# BE-U1000 register map
Vendor: BAIKAL ELECTRONICS, JSC; File version: 1.0
CPU: RISC-V r0p0, little endian, no MPU, no FPU, 3 interrupt priority bits
Registers are 32-bit, read-write, reset 0x0 unless marked. A register's access mark holds for its fields unless they carry their own. Offsets are from the block's base; [hi:lo] are bit positions; {n}, {i} and the like mark numbered series; 'fields as' and 'values as' point back to an identical list.

## CANFD0 — Controller Area Network
Base 0x11010000
Same registers: CANFD1 0x13010000
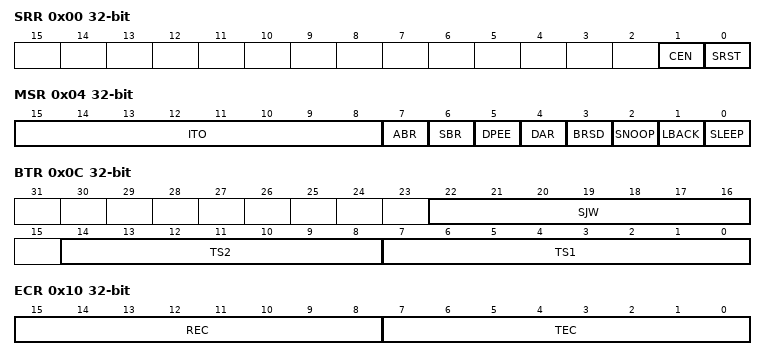
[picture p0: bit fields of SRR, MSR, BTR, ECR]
0x00 SRR — Software Reset Register
  [1] CEN — CAN enable
    0=DISABLE; 1=ENABLE
  [0] SRST — Reset
    0=DISABLE; 1=ENABLE
0x04 MSR — Mode Select Register
  [15:8] ITO — Internal timing optimization
  [7] ABR — Auto bus-off recovery request
    0=DISABLE; 1=ENABLE
  [6] SBR — Start bus-off recovery request
    0=DISABLE; 1=ENABLE
  [5] DPEE — Disable protocol exception event detection/generation
    0=DISABLE; 1=ENABLE
  [4] DAR — Disable auto retransmission
    0=DISABLE; 1=ENABLE
  [3] BRSD — CAN FD bitrate switch disable override
    0=DISABLE; 1=ENABLE
  [2] SNOOP — Snoop mode select/request
    0=DISABLE; 1=ENABLE
  [1] LBACK — Loopback mode select/request
    0=DISABLE; 1=ENABLE
  [0] SLEEP — Sleep mode select/request
    0=DISABLE; 1=ENABLE
0x08 BRPR — Arbitration Phase Baud Rate Prescaler Register
  [7:0] PR — Arbitration phase baudrate prescaler
0x0C BTR — Arbitration Phase Bit Timing Register
  [22:16] SJW — Synchronization jump width
  [14:8] TS2 — Time segment 2
  [7:0] TS1 — Time segment 1
0x10 ECR — Error Counter Register
  [15:8] REC — Receive error count
  [7:0] TEC — Transmit error count
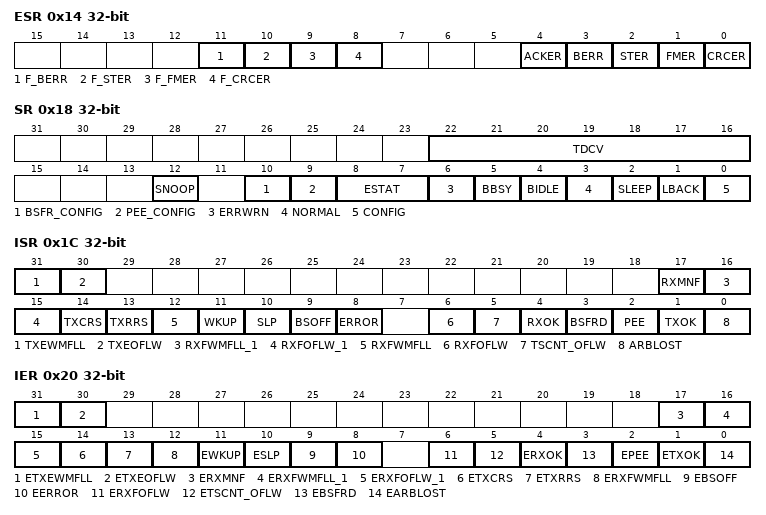
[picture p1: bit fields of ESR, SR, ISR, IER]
0x14 ESR — Error Status Register
  [all] fields
    0=DISABLE; 1=ENABLE
  [11] F_BERR — Bit error in CAN FD data phase
  [10] F_STER — Stuff error in CAN FD data phase
  [9] F_FMER — Form error in CAN FD data phase
  [8] F_CRCER — CRC error in CAN FD data phase
  [4] ACKER — ACK error
  [3] BERR — Bit error
  [2] STER — Stuff error
  [1] FMER — Form error
  [0] CRCER — CRC error
0x18 SR — Status Register
  [22:16] TDCV — Transmitter delay compensation value
  [12] SNOOP — Snoop mode
    0=DISABLE; 1=ENABLE
  [10] BSFR_CONFIG — Bus-off recovery mode indicator
    0=DISABLE; 1=ENABLE
  [9] PEE_CONFIG — PEE mode indicator
    0=DISABLE; 1=ENABLE
  [8:7] ESTAT — Error status
    0=CONFIG (Configuration mode, error state is undefined); 1=ACTIVE (Error active state); 2=BUSOFF (Bus-off state); 3=PASSIVE (Error passive state)
  [6] ERRWRN — Error warning
    0=DISABLE; 1=ENABLE
  [5] BBSY — Bus busy
    0=DISABLE; 1=ENABLE
  [4] BIDLE — Bus idle
    0=DISABLE; 1=ENABLE
  [3] NORMAL — Normal mode
    0=DISABLE; 1=ENABLE
  [2] SLEEP — Sleep mode
    0=DISABLE; 1=ENABLE
  [1] LBACK — Loopback mode
    0=DISABLE; 1=ENABLE
  [0] CONFIG — Configuration mode indicator
    0=DISABLE; 1=ENABLE
0x1C ISR — Interrupt Status Register
  [all] fields
    0=DISABLE; 1=ENABLE
  [31] TXEWMFLL — Tx event FIFO watermark full interrupt
  [30] TXEOFLW — Tx event FIFO overflow interrupt
  [17] RXMNF — Rx match not finished interrupt
  [16] RXFWMFLL_1 — Rx FIFO-1 watermark full interrupt
  [15] RXFOFLW_1 — Rx FIFO-1 overflow interrupt
  [14] TXCRS — Tx cancellation request served interrupt
  [13] TXRRS — Tx buffer ready request served interrupt
  [12] RXFWMFLL — Rx FIFO-0 watermark full interrupt
  [11] WKUP — Wake-up interrupt
  [10] SLP — Sleep interrupt
  [9] BSOFF — Bus-off interrupt
  [8] ERROR — Error interrupt
  [6] RXFOFLW — Rx FIFO-0 overflow interrupt
  [5] TSCNT_OFLW — Timestamp counter overflow interrupt
  [4] RXOK — New message received interrupt
  [3] BSFRD — Bus-off recovery done interrupt
  [2] PEE — Protocol exception event interrupt
  [1] TXOK — Transmission successful interrupt
  [0] ARBLOST — Arbitration lost interrupt
0x20 IER — Interrupt Enable Register
  [all] fields
    0=DISABLE; 1=ENABLE
  [31] ETXEWMFLL — Tx event FIFO watermark full interrupt enable
  [30] ETXEOFLW — Tx event FIFO overflow interrupt enable
  [17] ERXMNF — Rx match not finished interrupt enable
  [16] ERXFWMFLL_1 — Rx FIFO-1 watermark full interrupt enable
  [15] ERXFOFLW_1 — Rx FIFO-1 overflow interrupt enable
  [14] ETXCRS — Tx cancellation request served interrupt enable
  [13] ETXRRS — Tx buffer ready request served interrupt enable
  [12] ERXFWMFLL — Rx FIFO-0 watermark full interrupt enable
  [11] EWKUP — Wake-up interrupt enable
  [10] ESLP — Sleep interrupt enable
  [9] EBSOFF — Bus-off interrupt enable
  [8] EERROR — Error interrupt enable
  [6] ERXFOFLW — Rx FIFO-0 overflow interrupt enable
  [5] ETSCNT_OFLW — Timestamp counter overflow interrupt enable
  [4] ERXOK — New message received interrupt enable
  [3] EBSFRD — Bus-off recovery done interrupt enable
  [2] EPEE — Protocol exception event interrupt enable
  [1] ETXOK — Transmission successful interrupt enable
  [0] EARBLOST — Arbitration lost interrupt enable
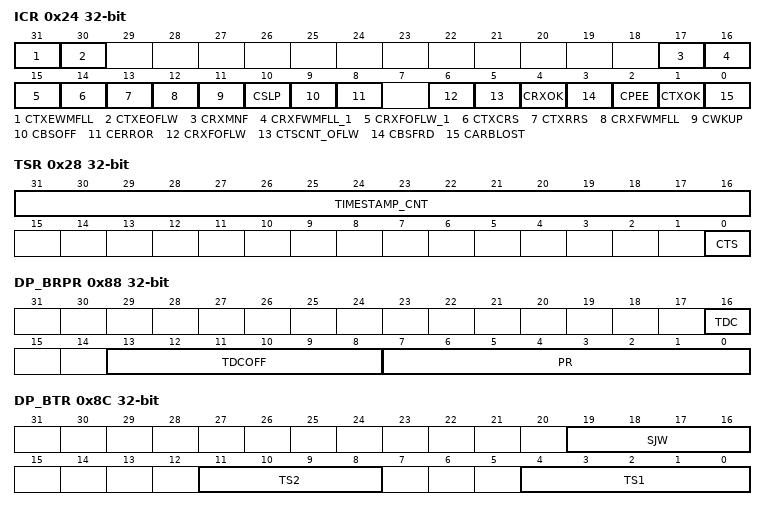
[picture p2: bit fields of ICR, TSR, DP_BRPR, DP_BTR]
0x24 ICR — Interrupt Clear Register
  [all] fields
    0=DISABLE; 1=ENABLE
  [31] CTXEWMFLL — Clear Tx event FIFO watermark full interrupt status bit
  [30] CTXEOFLW — Clear Tx event FIFO overflow interrupt status bit
  [17] CRXMNF — Clear Rx match not finished interrupt status bit
  [16] CRXFWMFLL_1 — Clear Rx FIFO-1 watermark full interrupt status bit
  [15] CRXFOFLW_1 — Clear Rx FIFO-1 overflow interrupt status bit
  [14] CTXCRS — Clear Tx cancellation request served interrupt status bit
  [13] CTXRRS — Clear Tx buffer ready request served interrupt status bit
  [12] CRXFWMFLL — Clear Rx FIFO-0 watermark full interrupt status bit
  [11] CWKUP — Clear wake-up interrupt status bit
  [10] CSLP — Clear sleep interrupt status bit
  [9] CBSOFF — Clear bus-off interrupt status bit
  [8] CERROR — Clear error interrupt status bit
  [6] CRXFOFLW — Clear Rx FIFO-0 overflow interrupt status bit
  [5] CTSCNT_OFLW — Clear timestamp counter overflow interrupt status bit
  [4] CRXOK — Clear new message received interrupt status bit
  [3] CBSFRD — Clear bus-off recovery done interrupt status bit
  [2] CPEE — Clear protocol exception event interrupt status bit
  [1] CTXOK — Clear transmission successful interrupt status bit
  [0] CARBLOST — Clear arbitration lost interrupt status bit
0x28 TSR — Timestamp Register
  [31:16] TIMESTAMP_CNT — Timestamp counter value
  [0] CTS — Clear timestamp counter
    0=DISABLE; 1=ENABLE
0x88 DP_BRPR — Data Phase Baud Rate Prescaler Register
  [16] TDC — Transmitter delay compensation enable
    0=DISABLE; 1=ENABLE
  [13:8] TDCOFF — Transmitter delay compensation offset
  [7:0] PR — Data phase baudrate prescaler
0x8C DP_BTR — Data Phase Bit Timing Register
  [19:16] SJW — Data phase synchronization jump width
  [11:8] TS2 — Data phase time segment 2
  [4:0] TS1 — Data phase time segment 1
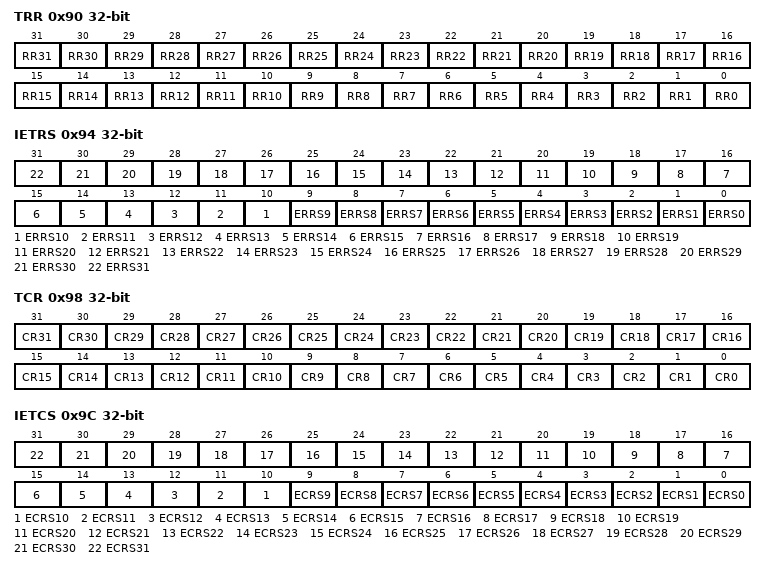
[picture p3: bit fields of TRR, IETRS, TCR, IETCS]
0x90 TRR — Tx Buffer Ready Request Register
  [all] fields
    0=DISABLE; 1=ENABLE
  [n] RR{n} (n=0..31) — Tx buffer {n} ready request
0x94 IETRS — Interrupt Enable Tx Buffer Ready Request Served Register
  [all] fields
    0=DISABLE; 1=ENABLE
  [n] ERRS{n} (n=0..31) — Tx buffer {n} ready request served interrupt enable
0x98 TCR — Tx Buffer Cancel Request Register
  [all] fields
    0=DISABLE; 1=ENABLE
  [n] CR{n} (n=0..31) — Tx buffer {n} cancel request
0x9C IETCS — Interrupt Enable Tx Buffer Cancel Request Served Register
  [all] fields
    0=DISABLE; 1=ENABLE
  [n] ECRS{n} (n=0..31) — Tx buffer {n} cancellation request served interrupt enable
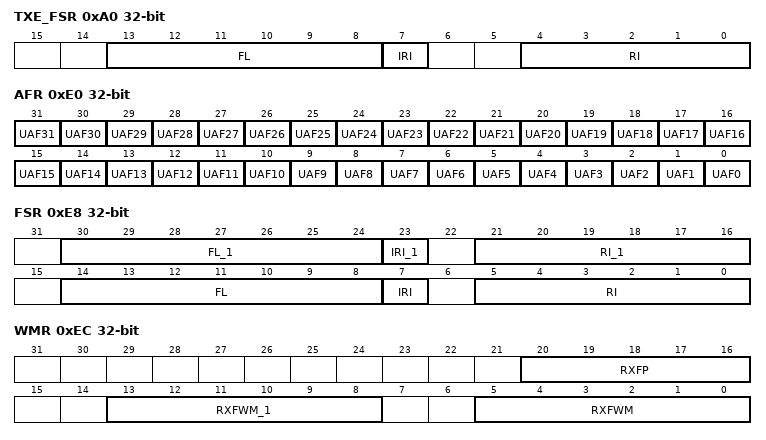
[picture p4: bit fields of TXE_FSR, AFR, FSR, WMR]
0xA0 TXE_FSR — Tx Event FIFO Status Register
  [13:8] FL — Fill level
  [7] IRI — Increment read index by 1
    0=DISABLE; 1=ENABLE
  [4:0] RI — Read index
0xA4 TXE_WMR — Tx Event FIFO Watermark Register
  [4:0] FWM — Tx event FIFO full watermark
0xE0 AFR — Acceptance Filter Register
  [all] fields
    0=DISABLE; 1=ENABLE
  [n] UAF{n} (n=0..31) — Acceptance filter mask pair {n} enable
0xE8 FSR — Rx FIFO Status Register
  [30:24] FL_1 — Rx FIFO-1 fill level
  [23] IRI_1 — Rx FIFO-1 increment read index by 1
    0=DISABLE; 1=ENABLE
  [21:16] RI_1 — Rx FIFO-1 read index
  [14:8] FL — Rx FIFO-0 fill level
  [7] IRI — Rx FIFO-0 increment read index by 1
    0=DISABLE; 1=ENABLE
  [5:0] RI — Rx FIFO-0 read index
0xEC WMR — Rx FIFO Watermark Register
  [20:16] RXFP — Receive filter partition
  [13:8] RXFWM_1 — Rx FIFO-1 full watermark
  [5:0] RXFWM — Rx FIFO-0 full watermark
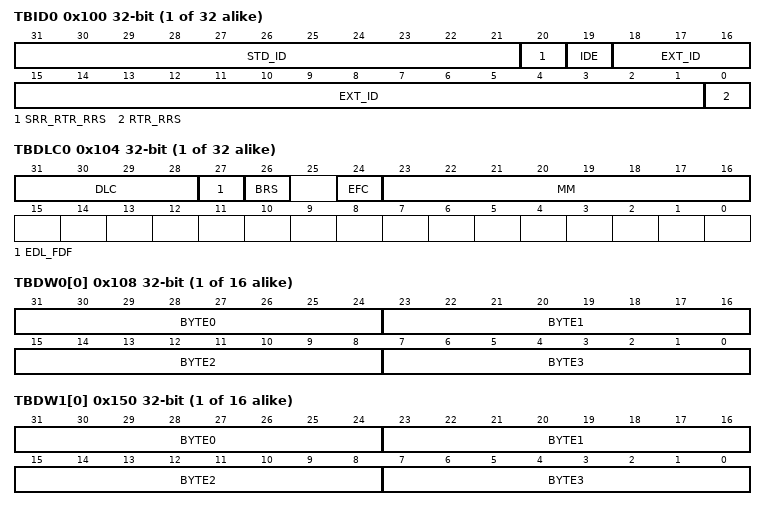
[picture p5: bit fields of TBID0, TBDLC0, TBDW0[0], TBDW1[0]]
{0x100+0x48*i} TBID{i} (i=0..31) — Tx Message Space TBID{i} Register
  [31:21] STD_ID — Standard message ID
  [20] SRR_RTR_RRS — Substitute remote transmission request
    0=DATA (The frame is a CAN standard data frame); 1=REMOTE (The frame is a CAN standard remote frame)
  [19] IDE — Identifier extension
    0=STD (Standard identifier); 1=EXT (Extended identifier)
  [18:1] EXT_ID — Extended message ID
  [0] RTR_RRS — Remote transmission request
    0=DATA (The frame is a CAN data frame); 1=REMOTE (The frame is a CAN remote frame)
{0x104+0x48*i} TBDLC{i} (i=0..31) — Tx Message Space TBDLC{i} Register
  [31:28] DLC — Data length code
  [27] EDL_FDF — Extended data length / FD frame format
    0=CAN (CAN format frame); 1=CANFD (CAN FD format frame)
  [26] BRS — Bitrate switch
    0=DISABLE (Bit rate is not switched); 1=ENABLE (Bit rate is switched)
  [24] EFC — Event FIFO control
    0=DISABLE (Don't store Tx events); 1=ENABLE (Store Tx events)
  [23:16] MM — Message marker
{0x108+4i} TBDW0[{i}] (i=0..15) — Tx Message Space TBDW0 Register
  [31-8n:24-8n] BYTE{n} (n=0..3) — Data byte {n}
{0x150+4i} TBDW1[{i}] (i=0..15) — Tx Message Space TBDW1 Register
  [31-8n:24-8n] BYTE{n} (n=0..3) — Data byte {n}
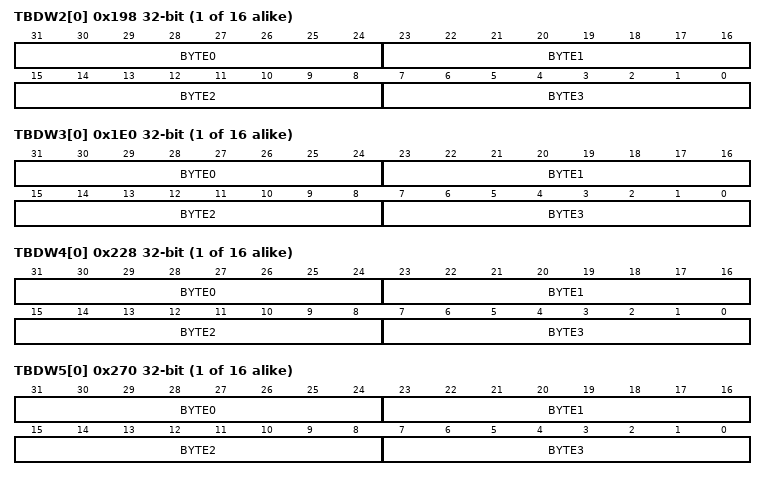
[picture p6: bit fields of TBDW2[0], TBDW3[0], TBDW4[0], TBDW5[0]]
{0x198+4i} TBDW2[{i}] (i=0..15) — Tx Message Space TBDW2 Register
  [31-8n:24-8n] BYTE{n} (n=0..3) — Data byte {n}
{0x1E0+4i} TBDW3[{i}] (i=0..15) — Tx Message Space TBDW3 Register
  [31-8n:24-8n] BYTE{n} (n=0..3) — Data byte {n}
{0x228+4i} TBDW4[{i}] (i=0..15) — Tx Message Space TBDW4 Register
  [31-8n:24-8n] BYTE{n} (n=0..3) — Data byte {n}
{0x270+4i} TBDW5[{i}] (i=0..15) — Tx Message Space TBDW5 Register
  [31-8n:24-8n] BYTE{n} (n=0..3) — Data byte {n}
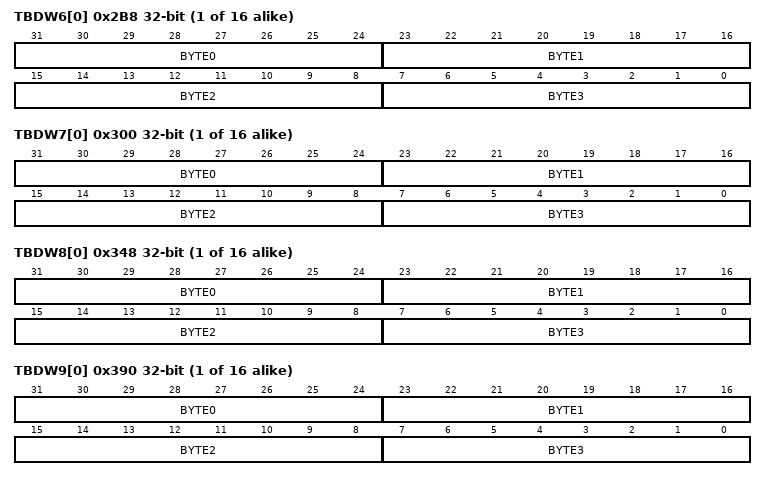
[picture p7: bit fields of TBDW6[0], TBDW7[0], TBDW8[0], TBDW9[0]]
{0x2B8+4i} TBDW6[{i}] (i=0..15) — Tx Message Space TBDW6 Register
  [31-8n:24-8n] BYTE{n} (n=0..3) — Data byte {n}
{0x300+4i} TBDW7[{i}] (i=0..15) — Tx Message Space TBDW7 Register
  [31-8n:24-8n] BYTE{n} (n=0..3) — Data byte {n}
{0x348+4i} TBDW8[{i}] (i=0..15) — Tx Message Space TBDW8 Register
  [31-8n:24-8n] BYTE{n} (n=0..3) — Data byte {n}
{0x390+4i} TBDW9[{i}] (i=0..15) — Tx Message Space TBDW9 Register
  [31-8n:24-8n] BYTE{n} (n=0..3) — Data byte {n}
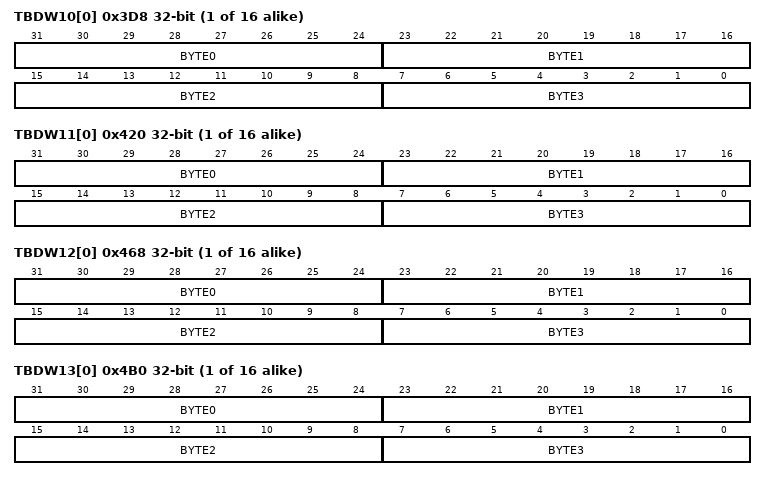
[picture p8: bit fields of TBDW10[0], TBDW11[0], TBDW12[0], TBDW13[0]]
{0x3D8+4i} TBDW10[{i}] (i=0..15) — Tx Message Space TBDW10 Register
  [31-8n:24-8n] BYTE{n} (n=0..3) — Data byte {n}
{0x420+4i} TBDW11[{i}] (i=0..15) — Tx Message Space TBDW11 Register
  [31-8n:24-8n] BYTE{n} (n=0..3) — Data byte {n}
{0x468+4i} TBDW12[{i}] (i=0..15) — Tx Message Space TBDW12 Register
  [31-8n:24-8n] BYTE{n} (n=0..3) — Data byte {n}
{0x4B0+4i} TBDW13[{i}] (i=0..15) — Tx Message Space TBDW13 Register
  [31-8n:24-8n] BYTE{n} (n=0..3) — Data byte {n}
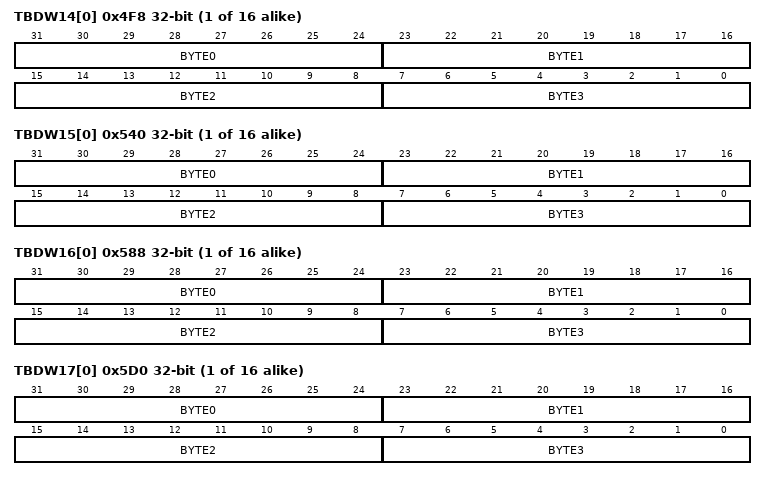
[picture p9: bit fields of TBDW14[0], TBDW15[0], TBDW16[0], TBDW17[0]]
{0x4F8+4i} TBDW14[{i}] (i=0..15) — Tx Message Space TBDW14 Register
  [31-8n:24-8n] BYTE{n} (n=0..3) — Data byte {n}
{0x540+4i} TBDW15[{i}] (i=0..15) — Tx Message Space TBDW15 Register
  [31-8n:24-8n] BYTE{n} (n=0..3) — Data byte {n}
{0x588+4i} TBDW16[{i}] (i=0..15) — Tx Message Space TBDW16 Register
  [31-8n:24-8n] BYTE{n} (n=0..3) — Data byte {n}
{0x5D0+4i} TBDW17[{i}] (i=0..15) — Tx Message Space TBDW17 Register
  [31-8n:24-8n] BYTE{n} (n=0..3) — Data byte {n}
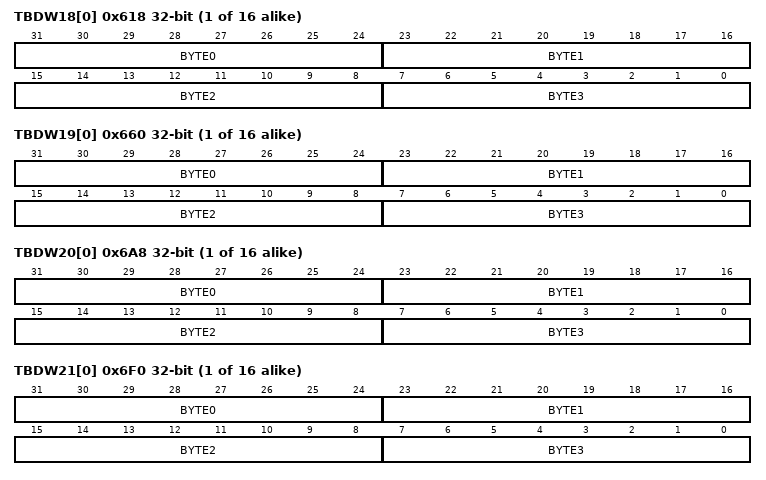
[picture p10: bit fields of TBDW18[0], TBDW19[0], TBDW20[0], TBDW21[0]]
{0x618+4i} TBDW18[{i}] (i=0..15) — Tx Message Space TBDW18 Register
  [31-8n:24-8n] BYTE{n} (n=0..3) — Data byte {n}
{0x660+4i} TBDW19[{i}] (i=0..15) — Tx Message Space TBDW19 Register
  [31-8n:24-8n] BYTE{n} (n=0..3) — Data byte {n}
{0x6A8+4i} TBDW20[{i}] (i=0..15) — Tx Message Space TBDW20 Register
  [31-8n:24-8n] BYTE{n} (n=0..3) — Data byte {n}
{0x6F0+4i} TBDW21[{i}] (i=0..15) — Tx Message Space TBDW21 Register
  [31-8n:24-8n] BYTE{n} (n=0..3) — Data byte {n}
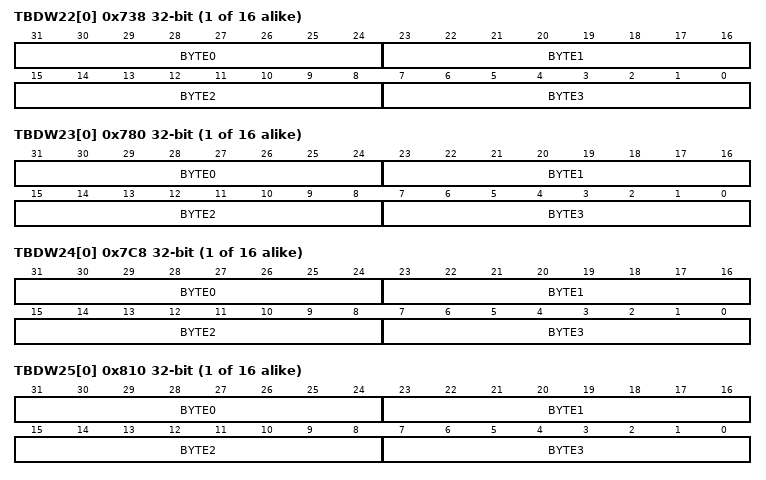
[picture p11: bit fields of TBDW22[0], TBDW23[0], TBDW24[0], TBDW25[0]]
{0x738+4i} TBDW22[{i}] (i=0..15) — Tx Message Space TBDW22 Register
  [31-8n:24-8n] BYTE{n} (n=0..3) — Data byte {n}
{0x780+4i} TBDW23[{i}] (i=0..15) — Tx Message Space TBDW23 Register
  [31-8n:24-8n] BYTE{n} (n=0..3) — Data byte {n}
{0x7C8+4i} TBDW24[{i}] (i=0..15) — Tx Message Space TBDW24 Register
  [31-8n:24-8n] BYTE{n} (n=0..3) — Data byte {n}
{0x810+4i} TBDW25[{i}] (i=0..15) — Tx Message Space TBDW25 Register
  [31-8n:24-8n] BYTE{n} (n=0..3) — Data byte {n}
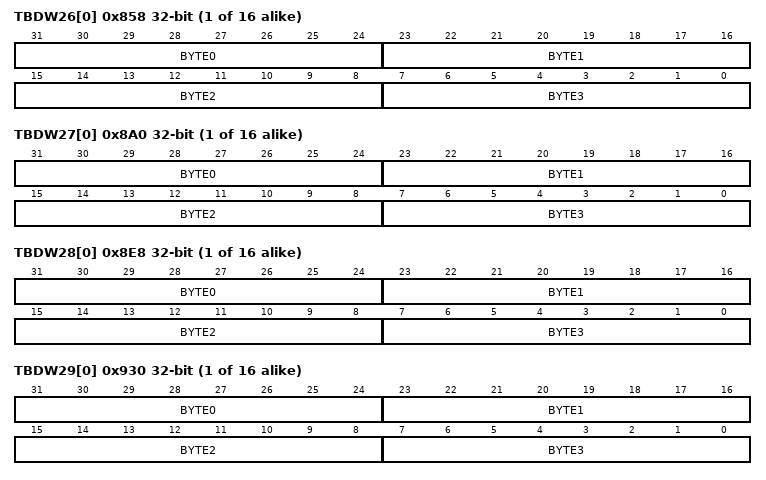
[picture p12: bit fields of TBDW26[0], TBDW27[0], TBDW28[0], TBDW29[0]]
{0x858+4i} TBDW26[{i}] (i=0..15) — Tx Message Space TBDW26 Register
  [31-8n:24-8n] BYTE{n} (n=0..3) — Data byte {n}
{0x8A0+4i} TBDW27[{i}] (i=0..15) — Tx Message Space TBDW27 Register
  [31-8n:24-8n] BYTE{n} (n=0..3) — Data byte {n}
{0x8E8+4i} TBDW28[{i}] (i=0..15) — Tx Message Space TBDW28 Register
  [31-8n:24-8n] BYTE{n} (n=0..3) — Data byte {n}
{0x930+4i} TBDW29[{i}] (i=0..15) — Tx Message Space TBDW29 Register
  [31-8n:24-8n] BYTE{n} (n=0..3) — Data byte {n}
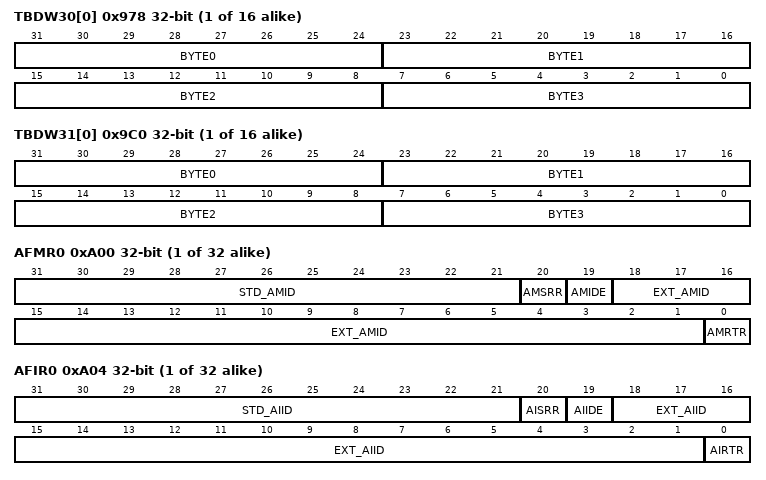
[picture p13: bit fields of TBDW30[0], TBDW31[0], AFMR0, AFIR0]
{0x978+4i} TBDW30[{i}] (i=0..15) — Tx Message Space TBDW30 Register
  [31-8n:24-8n] BYTE{n} (n=0..3) — Data byte {n}
{0x9C0+4i} TBDW31[{i}] (i=0..15) — Tx Message Space TBDW31 Register
  [31-8n:24-8n] BYTE{n} (n=0..3) — Data byte {n}
{0xA00+8i} AFMR{i} (i=0..31) — Acceptance Filter Mask AFMR{i} Register
  [31:21] STD_AMID — Standard message ID mask
  [20] AMSRR — Substitute remote transmission request mask
    0=DISABLE; 1=ENABLE
  [19] AMIDE — Identifier extension mask
    0=DISABLE; 1=ENABLE
  [18:1] EXT_AMID — Extended message ID mask
  [0] AMRTR — Remote transmission request mask
    0=DISABLE; 1=ENABLE
{0xA04+8i} AFIR{i} (i=0..31) — Acceptance Filter ID AFIR{i} Register
  [31:21] STD_AIID — Standard message ID
  [20] AISRR — Substitute remote transmission request
    0=DISABLE; 1=ENABLE
  [19] AIIDE — Identifier extension
    0=DISABLE; 1=ENABLE
  [18:1] EXT_AIID — Extended message ID
  [0] AIRTR — Remote transmission request
    0=DISABLE; 1=ENABLE
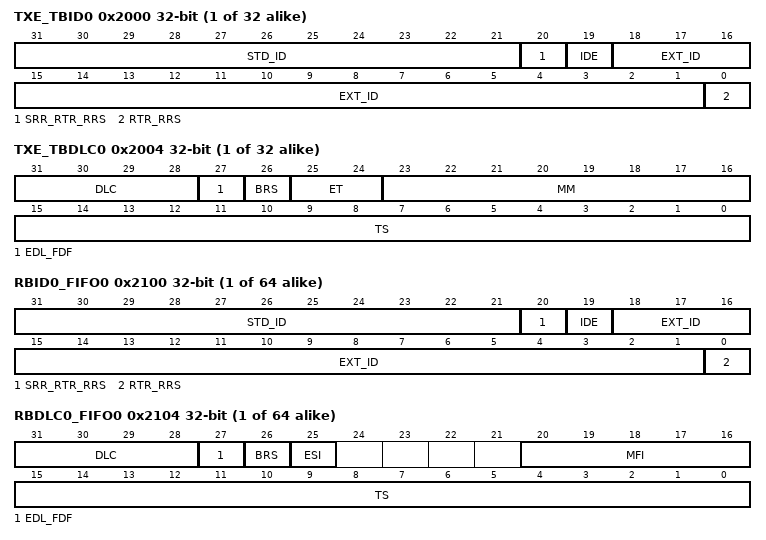
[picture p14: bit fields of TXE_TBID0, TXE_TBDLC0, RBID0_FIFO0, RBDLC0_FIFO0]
{0x2000+8i} TXE_TBID{i} (i=0..31) — Tx Event FIFO TB ID TXE_TBID{i} Register
  fields as TBID0
{0x2004+8i} TXE_TBDLC{i} (i=0..31) — Tx Event FIFO TB DLC TXE_TBDLC{i} Register
  [31:28] DLC — Data length code
  [27] EDL_FDF — Extended data length / FD frame format
    0=CAN (CAN format frame); 1=CANFD (CAN FD format frame)
  [26] BRS — Bitrate switch
    values as TBDLC0.BRS
  [25:24] ET — Event type
    1=FORCED (Transmitted in spite of cancellation request or DAR mode transmissions); 3=TRANSMITTED
  [23:16] MM — Message marker
  [15:0] TS — Timestamp captured after SOF bit
{0x2100+0x48*i} RBID{i}_FIFO0 (i=0..63) — Rx Message Space (FIFO-0) RB ID RBID{i}_FIFO0 Register
  fields as TBID0
{0x2104+0x48*i} RBDLC{i}_FIFO0 (i=0..63) — Rx Message Space (FIFO-0) RB DLC RBDLC{i}_FIFO0 Register
  [31:28] DLC — Data length code
  [27] EDL_FDF — Extended data length / FD frame format
    0=CAN (CAN format frame); 1=CANFD (CAN FD format frame)
  [26] BRS — Bitrate switch
    values as TBDLC0.BRS
  [25] ESI — Error state indicator
    0=ACTIVE (The frame was sent by the error active transmitter); 1=PASSIVE (The frame was sent by the error passive transmitter)
  [20:16] MFI — Matched filter index
  [15:0] TS — Timestamp captured after SOF bit
{0x2108+4i} RBDW0_FIFO0[{i}] (i=0..15) — Rx Message Space (FIFO-0) RB DWn RBDW0_FIFO0 Register
  [31-8n:24-8n] BYTE{n} (n=0..3) — Data byte {n}
{0x2150+4i} RBDW1_FIFO0[{i}] (i=0..15) — Rx Message Space (FIFO-0) RB DWn RBDW1_FIFO0 Register
  [31-8n:24-8n] BYTE{n} (n=0..3) — Data byte {n}
{0x2198+4i} RBDW2_FIFO0[{i}] (i=0..15) — Rx Message Space (FIFO-0) RB DWn RBDW2_FIFO0 Register
  [31-8n:24-8n] BYTE{n} (n=0..3) — Data byte {n}
{0x21E0+4i} RBDW3_FIFO0[{i}] (i=0..15) — Rx Message Space (FIFO-0) RB DWn RBDW3_FIFO0 Register
  [31-8n:24-8n] BYTE{n} (n=0..3) — Data byte {n}
{0x2228+4i} RBDW4_FIFO0[{i}] (i=0..15) — Rx Message Space (FIFO-0) RB DWn RBDW4_FIFO0 Register
  [31-8n:24-8n] BYTE{n} (n=0..3) — Data byte {n}
{0x2270+4i} RBDW5_FIFO0[{i}] (i=0..15) — Rx Message Space (FIFO-0) RB DWn RBDW5_FIFO0 Register
  [31-8n:24-8n] BYTE{n} (n=0..3) — Data byte {n}
{0x22B8+4i} RBDW6_FIFO0[{i}] (i=0..15) — Rx Message Space (FIFO-0) RB DWn RBDW6_FIFO0 Register
  [31-8n:24-8n] BYTE{n} (n=0..3) — Data byte {n}
{0x2300+4i} RBDW7_FIFO0[{i}] (i=0..15) — Rx Message Space (FIFO-0) RB DWn RBDW7_FIFO0 Register
  [31-8n:24-8n] BYTE{n} (n=0..3) — Data byte {n}
{0x2348+4i} RBDW8_FIFO0[{i}] (i=0..15) — Rx Message Space (FIFO-0) RB DWn RBDW8_FIFO0 Register
  [31-8n:24-8n] BYTE{n} (n=0..3) — Data byte {n}
{0x2390+4i} RBDW9_FIFO0[{i}] (i=0..15) — Rx Message Space (FIFO-0) RB DWn RBDW9_FIFO0 Register
  [31-8n:24-8n] BYTE{n} (n=0..3) — Data byte {n}
{0x23D8+4i} RBDW10_FIFO0[{i}] (i=0..15) — Rx Message Space (FIFO-0) RB DWn RBDW10_FIFO0 Register
  [31-8n:24-8n] BYTE{n} (n=0..3) — Data byte {n}
{0x2420+4i} RBDW11_FIFO0[{i}] (i=0..15) — Rx Message Space (FIFO-0) RB DWn RBDW11_FIFO0 Register
  [31-8n:24-8n] BYTE{n} (n=0..3) — Data byte {n}
{0x2468+4i} RBDW12_FIFO0[{i}] (i=0..15) — Rx Message Space (FIFO-0) RB DWn RBDW12_FIFO0 Register
  [31-8n:24-8n] BYTE{n} (n=0..3) — Data byte {n}
{0x24B0+4i} RBDW13_FIFO0[{i}] (i=0..15) — Rx Message Space (FIFO-0) RB DWn RBDW13_FIFO0 Register
  [31-8n:24-8n] BYTE{n} (n=0..3) — Data byte {n}
{0x24F8+4i} RBDW14_FIFO0[{i}] (i=0..15) — Rx Message Space (FIFO-0) RB DWn RBDW14_FIFO0 Register
  [31-8n:24-8n] BYTE{n} (n=0..3) — Data byte {n}
{0x2540+4i} RBDW15_FIFO0[{i}] (i=0..15) — Rx Message Space (FIFO-0) RB DWn RBDW15_FIFO0 Register
  [31-8n:24-8n] BYTE{n} (n=0..3) — Data byte {n}
{0x2588+4i} RBDW16_FIFO0[{i}] (i=0..15) — Rx Message Space (FIFO-0) RB DWn RBDW16_FIFO0 Register
  [31-8n:24-8n] BYTE{n} (n=0..3) — Data byte {n}
{0x25D0+4i} RBDW17_FIFO0[{i}] (i=0..15) — Rx Message Space (FIFO-0) RB DWn RBDW17_FIFO0 Register
  [31-8n:24-8n] BYTE{n} (n=0..3) — Data byte {n}
{0x2618+4i} RBDW18_FIFO0[{i}] (i=0..15) — Rx Message Space (FIFO-0) RB DWn RBDW18_FIFO0 Register
  [31-8n:24-8n] BYTE{n} (n=0..3) — Data byte {n}
{0x2660+4i} RBDW19_FIFO0[{i}] (i=0..15) — Rx Message Space (FIFO-0) RB DWn RBDW19_FIFO0 Register
  [31-8n:24-8n] BYTE{n} (n=0..3) — Data byte {n}
{0x26A8+4i} RBDW20_FIFO0[{i}] (i=0..15) — Rx Message Space (FIFO-0) RB DWn RBDW20_FIFO0 Register
  [31-8n:24-8n] BYTE{n} (n=0..3) — Data byte {n}
{0x26F0+4i} RBDW21_FIFO0[{i}] (i=0..15) — Rx Message Space (FIFO-0) RB DWn RBDW21_FIFO0 Register
  [31-8n:24-8n] BYTE{n} (n=0..3) — Data byte {n}
{0x2738+4i} RBDW22_FIFO0[{i}] (i=0..15) — Rx Message Space (FIFO-0) RB DWn RBDW22_FIFO0 Register
  [31-8n:24-8n] BYTE{n} (n=0..3) — Data byte {n}
{0x2780+4i} RBDW23_FIFO0[{i}] (i=0..15) — Rx Message Space (FIFO-0) RB DWn RBDW23_FIFO0 Register
  [31-8n:24-8n] BYTE{n} (n=0..3) — Data byte {n}
{0x27C8+4i} RBDW24_FIFO0[{i}] (i=0..15) — Rx Message Space (FIFO-0) RB DWn RBDW24_FIFO0 Register
  [31-8n:24-8n] BYTE{n} (n=0..3) — Data byte {n}
{0x2810+4i} RBDW25_FIFO0[{i}] (i=0..15) — Rx Message Space (FIFO-0) RB DWn RBDW25_FIFO0 Register
  [31-8n:24-8n] BYTE{n} (n=0..3) — Data byte {n}
{0x2858+4i} RBDW26_FIFO0[{i}] (i=0..15) — Rx Message Space (FIFO-0) RB DWn RBDW26_FIFO0 Register
  [31-8n:24-8n] BYTE{n} (n=0..3) — Data byte {n}
{0x28A0+4i} RBDW27_FIFO0[{i}] (i=0..15) — Rx Message Space (FIFO-0) RB DWn RBDW27_FIFO0 Register
  [31-8n:24-8n] BYTE{n} (n=0..3) — Data byte {n}
{0x28E8+4i} RBDW28_FIFO0[{i}] (i=0..15) — Rx Message Space (FIFO-0) RB DWn RBDW28_FIFO0 Register
  [31-8n:24-8n] BYTE{n} (n=0..3) — Data byte {n}
{0x2930+4i} RBDW29_FIFO0[{i}] (i=0..15) — Rx Message Space (FIFO-0) RB DWn RBDW29_FIFO0 Register
  [31-8n:24-8n] BYTE{n} (n=0..3) — Data byte {n}
{0x2978+4i} RBDW30_FIFO0[{i}] (i=0..15) — Rx Message Space (FIFO-0) RB DWn RBDW30_FIFO0 Register
  [31-8n:24-8n] BYTE{n} (n=0..3) — Data byte {n}
{0x29C0+4i} RBDW31_FIFO0[{i}] (i=0..15) — Rx Message Space (FIFO-0) RB DWn RBDW31_FIFO0 Register
  [31-8n:24-8n] BYTE{n} (n=0..3) — Data byte {n}
{0x2A08+4i} RBDW32_FIFO0[{i}] (i=0..15) — Rx Message Space (FIFO-0) RB DWn RBDW32_FIFO0 Register
  [31-8n:24-8n] BYTE{n} (n=0..3) — Data byte {n}
{0x2A50+4i} RBDW33_FIFO0[{i}] (i=0..15) — Rx Message Space (FIFO-0) RB DWn RBDW33_FIFO0 Register
  [31-8n:24-8n] BYTE{n} (n=0..3) — Data byte {n}
{0x2A98+4i} RBDW34_FIFO0[{i}] (i=0..15) — Rx Message Space (FIFO-0) RB DWn RBDW34_FIFO0 Register
  [31-8n:24-8n] BYTE{n} (n=0..3) — Data byte {n}
{0x2AE0+4i} RBDW35_FIFO0[{i}] (i=0..15) — Rx Message Space (FIFO-0) RB DWn RBDW35_FIFO0 Register
  [31-8n:24-8n] BYTE{n} (n=0..3) — Data byte {n}
{0x2B28+4i} RBDW36_FIFO0[{i}] (i=0..15) — Rx Message Space (FIFO-0) RB DWn RBDW36_FIFO0 Register
  [31-8n:24-8n] BYTE{n} (n=0..3) — Data byte {n}
{0x2B70+4i} RBDW37_FIFO0[{i}] (i=0..15) — Rx Message Space (FIFO-0) RB DWn RBDW37_FIFO0 Register
  [31-8n:24-8n] BYTE{n} (n=0..3) — Data byte {n}
{0x2BB8+4i} RBDW38_FIFO0[{i}] (i=0..15) — Rx Message Space (FIFO-0) RB DWn RBDW38_FIFO0 Register
  [31-8n:24-8n] BYTE{n} (n=0..3) — Data byte {n}
{0x2C00+4i} RBDW39_FIFO0[{i}] (i=0..15) — Rx Message Space (FIFO-0) RB DWn RBDW39_FIFO0 Register
  [31-8n:24-8n] BYTE{n} (n=0..3) — Data byte {n}
{0x2C48+4i} RBDW40_FIFO0[{i}] (i=0..15) — Rx Message Space (FIFO-0) RB DWn RBDW40_FIFO0 Register
  [31-8n:24-8n] BYTE{n} (n=0..3) — Data byte {n}
{0x2C90+4i} RBDW41_FIFO0[{i}] (i=0..15) — Rx Message Space (FIFO-0) RB DWn RBDW41_FIFO0 Register
  [31-8n:24-8n] BYTE{n} (n=0..3) — Data byte {n}
{0x2CD8+4i} RBDW42_FIFO0[{i}] (i=0..15) — Rx Message Space (FIFO-0) RB DWn RBDW42_FIFO0 Register
  [31-8n:24-8n] BYTE{n} (n=0..3) — Data byte {n}
{0x2D20+4i} RBDW43_FIFO0[{i}] (i=0..15) — Rx Message Space (FIFO-0) RB DWn RBDW43_FIFO0 Register
  [31-8n:24-8n] BYTE{n} (n=0..3) — Data byte {n}
{0x2D68+4i} RBDW44_FIFO0[{i}] (i=0..15) — Rx Message Space (FIFO-0) RB DWn RBDW44_FIFO0 Register
  [31-8n:24-8n] BYTE{n} (n=0..3) — Data byte {n}
{0x2DB0+4i} RBDW45_FIFO0[{i}] (i=0..15) — Rx Message Space (FIFO-0) RB DWn RBDW45_FIFO0 Register
  [31-8n:24-8n] BYTE{n} (n=0..3) — Data byte {n}
{0x2DF8+4i} RBDW46_FIFO0[{i}] (i=0..15) — Rx Message Space (FIFO-0) RB DWn RBDW46_FIFO0 Register
  [31-8n:24-8n] BYTE{n} (n=0..3) — Data byte {n}
{0x2E40+4i} RBDW47_FIFO0[{i}] (i=0..15) — Rx Message Space (FIFO-0) RB DWn RBDW47_FIFO0 Register
  [31-8n:24-8n] BYTE{n} (n=0..3) — Data byte {n}
{0x2E88+4i} RBDW48_FIFO0[{i}] (i=0..15) — Rx Message Space (FIFO-0) RB DWn RBDW48_FIFO0 Register
  [31-8n:24-8n] BYTE{n} (n=0..3) — Data byte {n}
{0x2ED0+4i} RBDW49_FIFO0[{i}] (i=0..15) — Rx Message Space (FIFO-0) RB DWn RBDW49_FIFO0 Register
  [31-8n:24-8n] BYTE{n} (n=0..3) — Data byte {n}
{0x2F18+4i} RBDW50_FIFO0[{i}] (i=0..15) — Rx Message Space (FIFO-0) RB DWn RBDW50_FIFO0 Register
  [31-8n:24-8n] BYTE{n} (n=0..3) — Data byte {n}
{0x2F60+4i} RBDW51_FIFO0[{i}] (i=0..15) — Rx Message Space (FIFO-0) RB DWn RBDW51_FIFO0 Register
  [31-8n:24-8n] BYTE{n} (n=0..3) — Data byte {n}
{0x2FA8+4i} RBDW52_FIFO0[{i}] (i=0..15) — Rx Message Space (FIFO-0) RB DWn RBDW52_FIFO0 Register
  [31-8n:24-8n] BYTE{n} (n=0..3) — Data byte {n}
{0x2FF0+4i} RBDW53_FIFO0[{i}] (i=0..15) — Rx Message Space (FIFO-0) RB DWn RBDW53_FIFO0 Register
  [31-8n:24-8n] BYTE{n} (n=0..3) — Data byte {n}
{0x3038+4i} RBDW54_FIFO0[{i}] (i=0..15) — Rx Message Space (FIFO-0) RB DWn RBDW54_FIFO0 Register
  [31-8n:24-8n] BYTE{n} (n=0..3) — Data byte {n}
{0x3080+4i} RBDW55_FIFO0[{i}] (i=0..15) — Rx Message Space (FIFO-0) RB DWn RBDW55_FIFO0 Register
  [31-8n:24-8n] BYTE{n} (n=0..3) — Data byte {n}
{0x30C8+4i} RBDW56_FIFO0[{i}] (i=0..15) — Rx Message Space (FIFO-0) RB DWn RBDW56_FIFO0 Register
  [31-8n:24-8n] BYTE{n} (n=0..3) — Data byte {n}
{0x3110+4i} RBDW57_FIFO0[{i}] (i=0..15) — Rx Message Space (FIFO-0) RB DWn RBDW57_FIFO0 Register
  [31-8n:24-8n] BYTE{n} (n=0..3) — Data byte {n}
{0x3158+4i} RBDW58_FIFO0[{i}] (i=0..15) — Rx Message Space (FIFO-0) RB DWn RBDW58_FIFO0 Register
  [31-8n:24-8n] BYTE{n} (n=0..3) — Data byte {n}
{0x31A0+4i} RBDW59_FIFO0[{i}] (i=0..15) — Rx Message Space (FIFO-0) RB DWn RBDW59_FIFO0 Register
  [31-8n:24-8n] BYTE{n} (n=0..3) — Data byte {n}
{0x31E8+4i} RBDW60_FIFO0[{i}] (i=0..15) — Rx Message Space (FIFO-0) RB DWn RBDW60_FIFO0 Register
  [31-8n:24-8n] BYTE{n} (n=0..3) — Data byte {n}
{0x3230+4i} RBDW61_FIFO0[{i}] (i=0..15) — Rx Message Space (FIFO-0) RB DWn RBDW61_FIFO0 Register
  [31-8n:24-8n] BYTE{n} (n=0..3) — Data byte {n}
{0x3278+4i} RBDW62_FIFO0[{i}] (i=0..15) — Rx Message Space (FIFO-0) RB DWn RBDW62_FIFO0 Register
  [31-8n:24-8n] BYTE{n} (n=0..3) — Data byte {n}
{0x32C0+4i} RBDW63_FIFO0[{i}] (i=0..15) — Rx Message Space (FIFO-0) RB DWn RBDW63_FIFO0 Register
  [31-8n:24-8n] BYTE{n} (n=0..3) — Data byte {n}
{0x4100+0x48*i} RBID{i}_FIFO1 (i=0..63) — Rx Message Space (FIFO-1) RB ID RBID{i}_FIFO1 Register
  fields as TBID0
{0x4104+0x48*i} RBDLC{i}_FIFO1 (i=0..63) — Rx Message Space (FIFO-1) RB DLC RBDLC{i}_FIFO1 Register
  fields as RBDLC0_FIFO0
{0x4108+4i} RBDW0_FIFO1[{i}] (i=0..15) — Rx Message Space (FIFO-1) RB DWn RBDW0_FIFO1 Register
  [31-8n:24-8n] BYTE{n} (n=0..3) — Data byte {n}
{0x4150+4i} RBDW1_FIFO1[{i}] (i=0..15) — Rx Message Space (FIFO-1) RB DWn RBDW1_FIFO1 Register
  [31-8n:24-8n] BYTE{n} (n=0..3) — Data byte {n}
{0x4198+4i} RBDW2_FIFO1[{i}] (i=0..15) — Rx Message Space (FIFO-1) RB DWn RBDW2_FIFO1 Register
  [31-8n:24-8n] BYTE{n} (n=0..3) — Data byte {n}
{0x41E0+4i} RBDW3_FIFO1[{i}] (i=0..15) — Rx Message Space (FIFO-1) RB DWn RBDW3_FIFO1 Register
  [31-8n:24-8n] BYTE{n} (n=0..3) — Data byte {n}
{0x4228+4i} RBDW4_FIFO1[{i}] (i=0..15) — Rx Message Space (FIFO-1) RB DWn RBDW4_FIFO1 Register
  [31-8n:24-8n] BYTE{n} (n=0..3) — Data byte {n}
{0x4270+4i} RBDW5_FIFO1[{i}] (i=0..15) — Rx Message Space (FIFO-1) RB DWn RBDW5_FIFO1 Register
  [31-8n:24-8n] BYTE{n} (n=0..3) — Data byte {n}
{0x42B8+4i} RBDW6_FIFO1[{i}] (i=0..15) — Rx Message Space (FIFO-1) RB DWn RBDW6_FIFO1 Register
  [31-8n:24-8n] BYTE{n} (n=0..3) — Data byte {n}
{0x4300+4i} RBDW7_FIFO1[{i}] (i=0..15) — Rx Message Space (FIFO-1) RB DWn RBDW7_FIFO1 Register
  [31-8n:24-8n] BYTE{n} (n=0..3) — Data byte {n}
{0x4348+4i} RBDW8_FIFO1[{i}] (i=0..15) — Rx Message Space (FIFO-1) RB DWn RBDW8_FIFO1 Register
  [31-8n:24-8n] BYTE{n} (n=0..3) — Data byte {n}
{0x4390+4i} RBDW9_FIFO1[{i}] (i=0..15) — Rx Message Space (FIFO-1) RB DWn RBDW9_FIFO1 Register
  [31-8n:24-8n] BYTE{n} (n=0..3) — Data byte {n}
{0x43D8+4i} RBDW10_FIFO1[{i}] (i=0..15) — Rx Message Space (FIFO-1) RB DWn RBDW10_FIFO1 Register
  [31-8n:24-8n] BYTE{n} (n=0..3) — Data byte {n}
{0x4420+4i} RBDW11_FIFO1[{i}] (i=0..15) — Rx Message Space (FIFO-1) RB DWn RBDW11_FIFO1 Register
  [31-8n:24-8n] BYTE{n} (n=0..3) — Data byte {n}
{0x4468+4i} RBDW12_FIFO1[{i}] (i=0..15) — Rx Message Space (FIFO-1) RB DWn RBDW12_FIFO1 Register
  [31-8n:24-8n] BYTE{n} (n=0..3) — Data byte {n}
{0x44B0+4i} RBDW13_FIFO1[{i}] (i=0..15) — Rx Message Space (FIFO-1) RB DWn RBDW13_FIFO1 Register
  [31-8n:24-8n] BYTE{n} (n=0..3) — Data byte {n}
{0x44F8+4i} RBDW14_FIFO1[{i}] (i=0..15) — Rx Message Space (FIFO-1) RB DWn RBDW14_FIFO1 Register
  [31-8n:24-8n] BYTE{n} (n=0..3) — Data byte {n}
{0x4540+4i} RBDW15_FIFO1[{i}] (i=0..15) — Rx Message Space (FIFO-1) RB DWn RBDW15_FIFO1 Register
  [31-8n:24-8n] BYTE{n} (n=0..3) — Data byte {n}
{0x4588+4i} RBDW16_FIFO1[{i}] (i=0..15) — Rx Message Space (FIFO-1) RB DWn RBDW16_FIFO1 Register
  [31-8n:24-8n] BYTE{n} (n=0..3) — Data byte {n}
{0x45D0+4i} RBDW17_FIFO1[{i}] (i=0..15) — Rx Message Space (FIFO-1) RB DWn RBDW17_FIFO1 Register
  [31-8n:24-8n] BYTE{n} (n=0..3) — Data byte {n}
{0x4618+4i} RBDW18_FIFO1[{i}] (i=0..15) — Rx Message Space (FIFO-1) RB DWn RBDW18_FIFO1 Register
  [31-8n:24-8n] BYTE{n} (n=0..3) — Data byte {n}
{0x4660+4i} RBDW19_FIFO1[{i}] (i=0..15) — Rx Message Space (FIFO-1) RB DWn RBDW19_FIFO1 Register
  [31-8n:24-8n] BYTE{n} (n=0..3) — Data byte {n}
{0x46A8+4i} RBDW20_FIFO1[{i}] (i=0..15) — Rx Message Space (FIFO-1) RB DWn RBDW20_FIFO1 Register
  [31-8n:24-8n] BYTE{n} (n=0..3) — Data byte {n}
{0x46F0+4i} RBDW21_FIFO1[{i}] (i=0..15) — Rx Message Space (FIFO-1) RB DWn RBDW21_FIFO1 Register
  [31-8n:24-8n] BYTE{n} (n=0..3) — Data byte {n}
{0x4738+4i} RBDW22_FIFO1[{i}] (i=0..15) — Rx Message Space (FIFO-1) RB DWn RBDW22_FIFO1 Register
  [31-8n:24-8n] BYTE{n} (n=0..3) — Data byte {n}
{0x4780+4i} RBDW23_FIFO1[{i}] (i=0..15) — Rx Message Space (FIFO-1) RB DWn RBDW23_FIFO1 Register
  [31-8n:24-8n] BYTE{n} (n=0..3) — Data byte {n}
{0x47C8+4i} RBDW24_FIFO1[{i}] (i=0..15) — Rx Message Space (FIFO-1) RB DWn RBDW24_FIFO1 Register
  [31-8n:24-8n] BYTE{n} (n=0..3) — Data byte {n}
{0x4810+4i} RBDW25_FIFO1[{i}] (i=0..15) — Rx Message Space (FIFO-1) RB DWn RBDW25_FIFO1 Register
  [31-8n:24-8n] BYTE{n} (n=0..3) — Data byte {n}
{0x4858+4i} RBDW26_FIFO1[{i}] (i=0..15) — Rx Message Space (FIFO-1) RB DWn RBDW26_FIFO1 Register
  [31-8n:24-8n] BYTE{n} (n=0..3) — Data byte {n}
{0x48A0+4i} RBDW27_FIFO1[{i}] (i=0..15) — Rx Message Space (FIFO-1) RB DWn RBDW27_FIFO1 Register
  [31-8n:24-8n] BYTE{n} (n=0..3) — Data byte {n}
{0x48E8+4i} RBDW28_FIFO1[{i}] (i=0..15) — Rx Message Space (FIFO-1) RB DWn RBDW28_FIFO1 Register
  [31-8n:24-8n] BYTE{n} (n=0..3) — Data byte {n}
{0x4930+4i} RBDW29_FIFO1[{i}] (i=0..15) — Rx Message Space (FIFO-1) RB DWn RBDW29_FIFO1 Register
  [31-8n:24-8n] BYTE{n} (n=0..3) — Data byte {n}
{0x4978+4i} RBDW30_FIFO1[{i}] (i=0..15) — Rx Message Space (FIFO-1) RB DWn RBDW30_FIFO1 Register
  [31-8n:24-8n] BYTE{n} (n=0..3) — Data byte {n}
{0x49C0+4i} RBDW31_FIFO1[{i}] (i=0..15) — Rx Message Space (FIFO-1) RB DWn RBDW31_FIFO1 Register
  [31-8n:24-8n] BYTE{n} (n=0..3) — Data byte {n}
{0x4A08+4i} RBDW32_FIFO1[{i}] (i=0..15) — Rx Message Space (FIFO-1) RB DWn RBDW32_FIFO1 Register
  [31-8n:24-8n] BYTE{n} (n=0..3) — Data byte {n}
{0x4A50+4i} RBDW33_FIFO1[{i}] (i=0..15) — Rx Message Space (FIFO-1) RB DWn RBDW33_FIFO1 Register
  [31-8n:24-8n] BYTE{n} (n=0..3) — Data byte {n}
{0x4A98+4i} RBDW34_FIFO1[{i}] (i=0..15) — Rx Message Space (FIFO-1) RB DWn RBDW34_FIFO1 Register
  [31-8n:24-8n] BYTE{n} (n=0..3) — Data byte {n}
{0x4AE0+4i} RBDW35_FIFO1[{i}] (i=0..15) — Rx Message Space (FIFO-1) RB DWn RBDW35_FIFO1 Register
  [31-8n:24-8n] BYTE{n} (n=0..3) — Data byte {n}
{0x4B28+4i} RBDW36_FIFO1[{i}] (i=0..15) — Rx Message Space (FIFO-1) RB DWn RBDW36_FIFO1 Register
  [31-8n:24-8n] BYTE{n} (n=0..3) — Data byte {n}
{0x4B70+4i} RBDW37_FIFO1[{i}] (i=0..15) — Rx Message Space (FIFO-1) RB DWn RBDW37_FIFO1 Register
  [31-8n:24-8n] BYTE{n} (n=0..3) — Data byte {n}
{0x4BB8+4i} RBDW38_FIFO1[{i}] (i=0..15) — Rx Message Space (FIFO-1) RB DWn RBDW38_FIFO1 Register
  [31-8n:24-8n] BYTE{n} (n=0..3) — Data byte {n}
{0x4C00+4i} RBDW39_FIFO1[{i}] (i=0..15) — Rx Message Space (FIFO-1) RB DWn RBDW39_FIFO1 Register
  [31-8n:24-8n] BYTE{n} (n=0..3) — Data byte {n}
{0x4C48+4i} RBDW40_FIFO1[{i}] (i=0..15) — Rx Message Space (FIFO-1) RB DWn RBDW40_FIFO1 Register
  [31-8n:24-8n] BYTE{n} (n=0..3) — Data byte {n}
{0x4C90+4i} RBDW41_FIFO1[{i}] (i=0..15) — Rx Message Space (FIFO-1) RB DWn RBDW41_FIFO1 Register
  [31-8n:24-8n] BYTE{n} (n=0..3) — Data byte {n}
{0x4CD8+4i} RBDW42_FIFO1[{i}] (i=0..15) — Rx Message Space (FIFO-1) RB DWn RBDW42_FIFO1 Register
  [31-8n:24-8n] BYTE{n} (n=0..3) — Data byte {n}
{0x4D20+4i} RBDW43_FIFO1[{i}] (i=0..15) — Rx Message Space (FIFO-1) RB DWn RBDW43_FIFO1 Register
  [31-8n:24-8n] BYTE{n} (n=0..3) — Data byte {n}
{0x4D68+4i} RBDW44_FIFO1[{i}] (i=0..15) — Rx Message Space (FIFO-1) RB DWn RBDW44_FIFO1 Register
  [31-8n:24-8n] BYTE{n} (n=0..3) — Data byte {n}
{0x4DB0+4i} RBDW45_FIFO1[{i}] (i=0..15) — Rx Message Space (FIFO-1) RB DWn RBDW45_FIFO1 Register
  [31-8n:24-8n] BYTE{n} (n=0..3) — Data byte {n}
{0x4DF8+4i} RBDW46_FIFO1[{i}] (i=0..15) — Rx Message Space (FIFO-1) RB DWn RBDW46_FIFO1 Register
  [31-8n:24-8n] BYTE{n} (n=0..3) — Data byte {n}
{0x4E40+4i} RBDW47_FIFO1[{i}] (i=0..15) — Rx Message Space (FIFO-1) RB DWn RBDW47_FIFO1 Register
  [31-8n:24-8n] BYTE{n} (n=0..3) — Data byte {n}
{0x4E88+4i} RBDW48_FIFO1[{i}] (i=0..15) — Rx Message Space (FIFO-1) RB DWn RBDW48_FIFO1 Register
  [31-8n:24-8n] BYTE{n} (n=0..3) — Data byte {n}
{0x4ED0+4i} RBDW49_FIFO1[{i}] (i=0..15) — Rx Message Space (FIFO-1) RB DWn RBDW49_FIFO1 Register
  [31-8n:24-8n] BYTE{n} (n=0..3) — Data byte {n}
{0x4F18+4i} RBDW50_FIFO1[{i}] (i=0..15) — Rx Message Space (FIFO-1) RB DWn RBDW50_FIFO1 Register
  [31-8n:24-8n] BYTE{n} (n=0..3) — Data byte {n}
{0x4F60+4i} RBDW51_FIFO1[{i}] (i=0..15) — Rx Message Space (FIFO-1) RB DWn RBDW51_FIFO1 Register
  [31-8n:24-8n] BYTE{n} (n=0..3) — Data byte {n}
{0x4FA8+4i} RBDW52_FIFO1[{i}] (i=0..15) — Rx Message Space (FIFO-1) RB DWn RBDW52_FIFO1 Register
  [31-8n:24-8n] BYTE{n} (n=0..3) — Data byte {n}
{0x4FF0+4i} RBDW53_FIFO1[{i}] (i=0..15) — Rx Message Space (FIFO-1) RB DWn RBDW53_FIFO1 Register
  [31-8n:24-8n] BYTE{n} (n=0..3) — Data byte {n}
{0x5038+4i} RBDW54_FIFO1[{i}] (i=0..15) — Rx Message Space (FIFO-1) RB DWn RBDW54_FIFO1 Register
  [31-8n:24-8n] BYTE{n} (n=0..3) — Data byte {n}
{0x5080+4i} RBDW55_FIFO1[{i}] (i=0..15) — Rx Message Space (FIFO-1) RB DWn RBDW55_FIFO1 Register
  [31-8n:24-8n] BYTE{n} (n=0..3) — Data byte {n}
{0x50C8+4i} RBDW56_FIFO1[{i}] (i=0..15) — Rx Message Space (FIFO-1) RB DWn RBDW56_FIFO1 Register
  [31-8n:24-8n] BYTE{n} (n=0..3) — Data byte {n}
{0x5110+4i} RBDW57_FIFO1[{i}] (i=0..15) — Rx Message Space (FIFO-1) RB DWn RBDW57_FIFO1 Register
  [31-8n:24-8n] BYTE{n} (n=0..3) — Data byte {n}
{0x5158+4i} RBDW58_FIFO1[{i}] (i=0..15) — Rx Message Space (FIFO-1) RB DWn RBDW58_FIFO1 Register
  [31-8n:24-8n] BYTE{n} (n=0..3) — Data byte {n}
{0x51A0+4i} RBDW59_FIFO1[{i}] (i=0..15) — Rx Message Space (FIFO-1) RB DWn RBDW59_FIFO1 Register
  [31-8n:24-8n] BYTE{n} (n=0..3) — Data byte {n}
{0x51E8+4i} RBDW60_FIFO1[{i}] (i=0..15) — Rx Message Space (FIFO-1) RB DWn RBDW60_FIFO1 Register
  [31-8n:24-8n] BYTE{n} (n=0..3) — Data byte {n}
{0x5230+4i} RBDW61_FIFO1[{i}] (i=0..15) — Rx Message Space (FIFO-1) RB DWn RBDW61_FIFO1 Register
  [31-8n:24-8n] BYTE{n} (n=0..3) — Data byte {n}
{0x5278+4i} RBDW62_FIFO1[{i}] (i=0..15) — Rx Message Space (FIFO-1) RB DWn RBDW62_FIFO1 Register
  [31-8n:24-8n] BYTE{n} (n=0..3) — Data byte {n}
{0x52C0+4i} RBDW63_FIFO1[{i}] (i=0..15) — Rx Message Space (FIFO-1) RB DWn RBDW63_FIFO1 Register
  [31-8n:24-8n] BYTE{n} (n=0..3) — Data byte {n}
